VERSION "HIPBNYYYYYYYYYYYYYYYYYYYYYYYYYYYYYYYYYYYYY/4/%%%/4/'%**4YYY///"

NS_ :

BS_:

BU_: DBG VCU BMS MCM DCU DAQ S2C

BO_ 2147483904 VCU_RR_Motor: 4 VCU
 SG_ VCU_RR_Current : 7|32@0- (0.001,0) [-2147.483|2147.483] "A" Vector__XXX

BO_ 2147483905 VCU_RL_Motor: 4 VCU
 SG_ VCU_RL_Current : 7|32@0- (0.001,0) [-2147.483|2147.483] "A" Vector__XXX

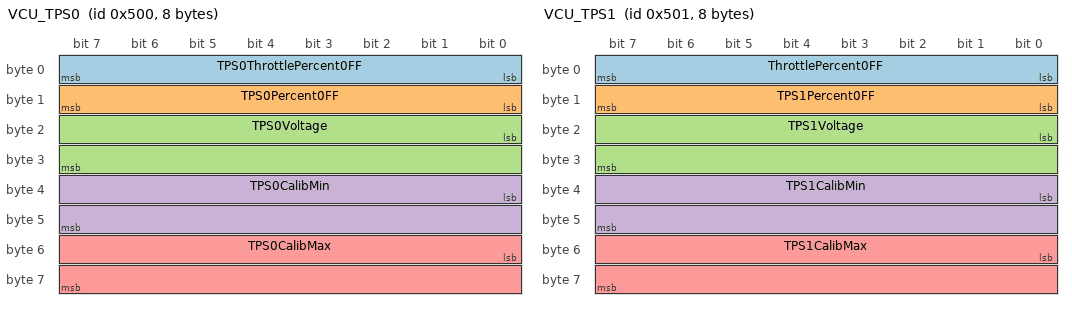
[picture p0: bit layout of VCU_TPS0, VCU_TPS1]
BO_ 1280 VCU_TPS0: 8 VCU
 SG_ TPS0ThrottlePercent0FF : 0|8@1+ (0.392156862746,0) [0|100.00000000023] "%" VCU
 SG_ TPS0Percent0FF : 8|8@1+ (0.392156862746,0) [0|100.00000000023] "%" VCU
 SG_ TPS0Voltage : 16|16@1+ (0.001,0) [0|65.535] "V" VCU
 SG_ TPS0CalibMin : 32|16@1+ (0.001,0) [0|65.535] "V" VCU
 SG_ TPS0CalibMax : 48|16@1+ (0.001,0) [0|65.535] "V" VCU

BO_ 1281 VCU_TPS1: 8 VCU
 SG_ ThrottlePercent0FF : 0|8@1+ (1,0) [0|255] "" VCU
 SG_ TPS1Percent0FF : 8|8@1+ (0.392156862746,0) [0|100.00000000023] "%" VCU
 SG_ TPS1Voltage : 16|16@1+ (0.001,0) [0|65.535] "V" VCU
 SG_ TPS1CalibMin : 32|16@1+ (0.001,0) [0|65.535] "V" VCU
 SG_ TPS1CalibMax : 48|16@1+ (0.001,0) [0|65.535] "V" VCU

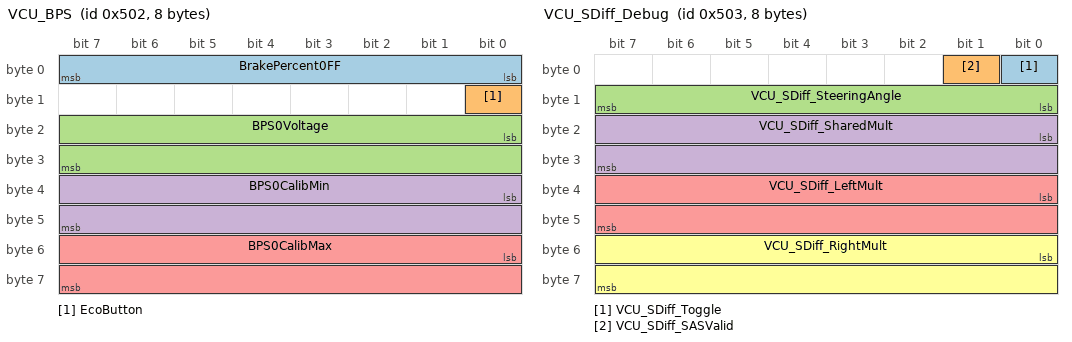
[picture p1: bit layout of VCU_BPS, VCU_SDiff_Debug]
BO_ 1282 VCU_BPS: 8 VCU
SG_ BrakePercent0FF : 0|8@1+ (0.392156862746,0) [0|100.00000000023] "%" VCU
SG_ EcoButton : 8|1@1+ (1,0) [0|1] "" VCU
SG_ BPS0Voltage : 16|16@1+ (0.001,0) [0|65.535] "V" VCU
SG_ BPS0CalibMin : 32|16@1+ (0.001,0) [0|65.535] "V" VCU
SG_ BPS0CalibMax : 48|16@1+ (0.001,0) [0|65.535] "V" VCU

BO_ 1283 VCU_SDiff_Debug: 8 VCU
 SG_ VCU_SDiff_Toggle : 0|1@1+ (1,0) [0|1] "" VCU
 SG_ VCU_SDiff_SASValid : 1|1@1+ (1,0) [0|1] "" VCU
 SG_ VCU_SDiff_SteeringAngle : 8|8@1- (1,0) [-90|90] "deg" VCU
 SG_ VCU_SDiff_SharedMult : 16|16@1+ (0.001,0) [0|1] "" VCU
 SG_ VCU_SDiff_LeftMult : 32|16@1+ (0.001,0) [0|1] "" VCU
 SG_ VCU_SDiff_RightMult : 48|16@1+ (0.001,0) [0|1] "" VCU

BO_ 1284 VCU_SAS: 8 VCU
 SG_ SAS_Voltage : 0|16@1+ (0.001,0) [0|5] "V" VCU

BO_ 1285 VCU_Safety_Checker: 8 VCU
 SG_ VCU_FAULT_TPS_OutOfRange : 0|1@1+ (1,0) [0|1] "" VCU
 SG_ VCU_FAULT_BPS_OutOfRange : 1|1@1+ (1,0) [0|1] "" VCU
 SG_ VCU_FAULT_TPS_PowerFailure : 2|1@1+ (1,0) [0|1] "" VCU
 SG_ VCU_FAULT_BPS_PowerFailure : 3|1@1+ (1,0) [0|1] "" VCU
 SG_ VCU_FAULT_TPS_SignalFailure : 4|1@1+ (1,0) [0|1] "" VCU
 SG_ VCU_FAULT_BPS_SignalFailure : 5|1@1+ (1,0) [0|1] "" VCU
 SG_ VCU_FAULT_TPS_NotCalibrated : 6|1@1+ (1,0) [0|1] "" VCU
 SG_ VCU_FAULT_BPS_NotCalibrated : 7|1@1+ (1,0) [0|1] "" VCU
 SG_ VCU_FAULT_TPS_OutOfSync : 8|1@1+ (1,0) [0|1] "" VCU
 SG_ VCU_FAULT_TPSBPS_Implausible : 10|1@1+ (1,0) [0|1] "" VCU
 SG_ VCU_FAULT_BSPD_SoftFault : 12|1@1+ (1,0) [0|1] "" VCU
 SG_ VCU_FAULT_LVS_BatteryEmpty : 16|1@1+ (1,0) [0|1] "" VCU
 SG_ VCU_FAULT_BMS_OverVoltage : 20|1@1+ (1,0) [0|1] "" VCU
 SG_ VCU_FAULT_BMS_UnderVoltage : 21|1@1+ (1,0) [0|1] "" VCU
 SG_ VCU_FAULT_BMS_OverTemperature : 22|1@1+ (1,0) [0|1] "" VCU
 SG_ VCU_FAULT_BMS_CommunicationLost : 23|1@1+ (1,0) [0|1] "" VCU
 SG_ VCU_FAULT_BMS_CellMismatch : 24|1@1+ (1,0) [0|1] "" VCU
 SG_ VCU_WARNING_LVS_BatteryLow : 32|1@1+ (1,0) [0|1] "" VCU
 SG_ VCU_WARNING_BMS_OverVoltage : 40|1@1+ (1,0) [0|1] "" VCU
 SG_ VCU_WARNING_BMS_UnderVoltage : 41|1@1+ (1,0) [0|1] "" VCU
 SG_ VCU_WARNING_BMS_OverTemperature : 42|1@1+ (1,0) [0|1] "" VCU
 SG_ VCU_WARNING_HVIL_OverrideEn : 38|1@1+ (1,0) [0|1] "" VCU
 SG_ VCU_WARNING_SAFETY_BypassEn : 39|1@1+ (1,0) [0|1] "" VCU
 SG_ VCU_NOTICE_HVIL_TermSenseLost : 48|1@1+ (1,0) [0|1] "" VCU
 SG_ VCU_NOTICE_BMS_Over75kW : 52|1@1+ (1,0) [0|1] "" VCU
 SG_ VCU_NOTICE_MCM_Over75kW : 53|1@1+ (1,0) [0|1] "" VCU

BO_ 1286 Low_Voltage: 8 DAQ
 SG_ Voltage : 0|16@1+ (0.001,0) [0|20] "V" VCU
 SG_ StateOfCharge : 16|8@1+ (1,0) [0|100] "%" VCU

BO_ 1287 MCM_RTD_HVIL: 8 VCU
 SG_ HVIL_Active : 0|1@1+ (1,0) [0|1] "" VCU

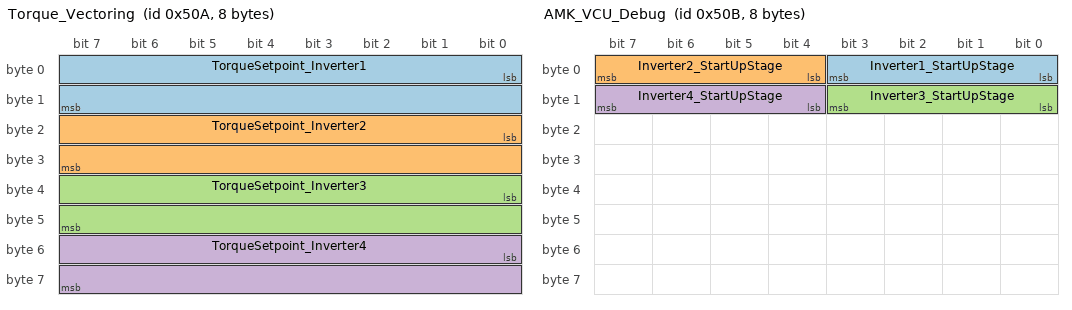
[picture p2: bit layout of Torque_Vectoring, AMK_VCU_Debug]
BO_ 1290 Torque_Vectoring: 8 mcm
 SG_ TorqueSetpoint_Inverter1 : 0|16@1- (0.01,0) [-5|5] "%Nm" Vector__XXX
 SG_ TorqueSetpoint_Inverter2 : 16|16@1- (0.01,0) [-5|5] "%Nm" Vector__XXX
 SG_ TorqueSetpoint_Inverter3 : 32|16@1- (0.01,0) [-5|5] "%Nm" Vector__XXX
 SG_ TorqueSetpoint_Inverter4 : 48|16@1- (0.01,0) [-5|5] "%Nm" Vector__XXX

BO_ 1291 AMK_VCU_Debug: 8 mcm
 SG_ Inverter1_StartUpStage : 0|4@1+ (1,0) [0|10] "" VCU
 SG_ Inverter2_StartUpStage : 4|4@1+ (1,0) [0|10] "" VCU
 SG_ Inverter3_StartUpStage : 8|4@1+ (1,0) [0|10] "" VCU
 SG_ Inverter4_StartUpStage : 12|4@1+ (1,0) [0|10] "" VCU

BO_ 1292 DRS_SAS: 8 DAQ
 SG_ DRS_Enable : 16|8@1+ (1,0) [0|1] "Enable" VCU
 SG_ DRS_Mode : 24|8@1+ (1,0) [0|3] "Selection" VCU

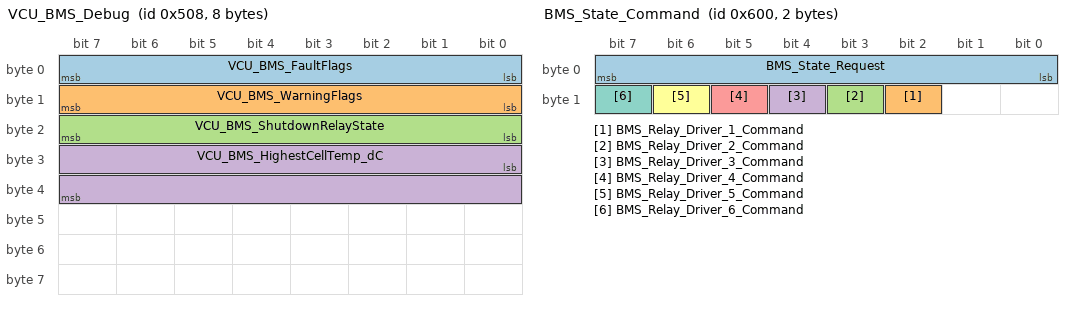
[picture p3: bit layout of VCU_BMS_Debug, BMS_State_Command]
BO_ 1288 VCU_BMS_Debug: 8 VCU
 SG_ VCU_BMS_FaultFlags : 0|8@1+ (1,0) [0|255] "" VCU
 SG_ VCU_BMS_WarningFlags : 8|8@1+ (1,0) [0|255] "" VCU
 SG_ VCU_BMS_ShutdownRelayState : 16|8@1+ (1,0) [0|255] "" VCU
 SG_ VCU_BMS_HighestCellTemp_dC : 24|16@1- (0.1,0) [-3276.8|3276.7] "C" VCU

BO_ 1536 BMS_State_Command: 2 VCU
 SG_ BMS_State_Request : 0|8@1+ (1,0) [0|4] "" Vector__XXX
 SG_ BMS_Relay_Driver_1_Command : 10|1@1+ (1,0) [0|1] "" Vector__XXX
 SG_ BMS_Relay_Driver_2_Command : 11|1@1+ (1,0) [0|1] "" Vector__XXX
 SG_ BMS_Relay_Driver_3_Command : 12|1@1+ (1,0) [0|1] "" Vector__XXX
 SG_ BMS_Relay_Driver_4_Command : 13|1@1+ (1,0) [0|1] "" Vector__XXX
 SG_ BMS_Relay_Driver_5_Command : 14|1@1+ (1,0) [0|1] "" Vector__XXX
 SG_ BMS_Relay_Driver_6_Command : 15|1@1+ (1,0) [0|1] "" Vector__XXX

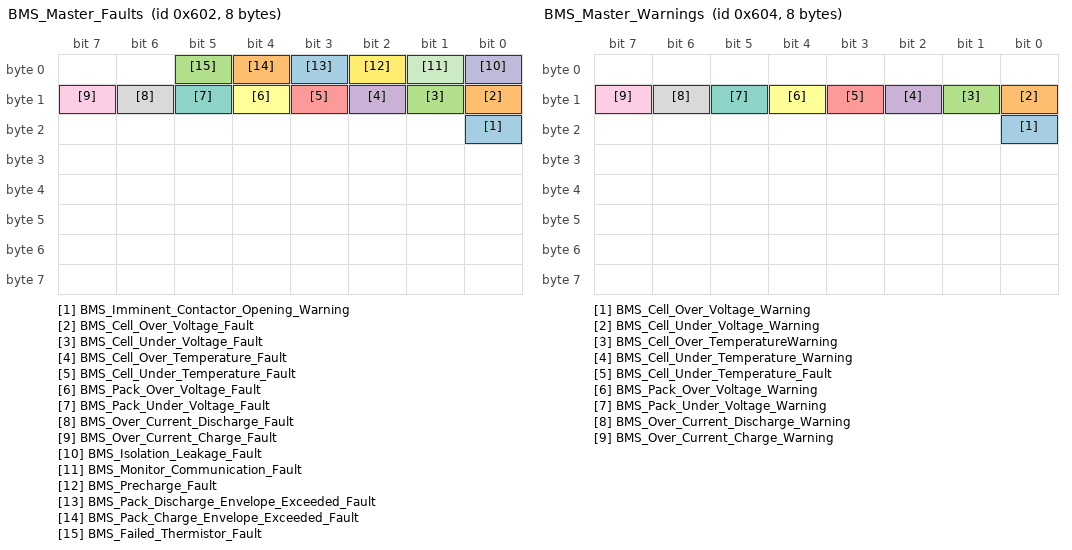
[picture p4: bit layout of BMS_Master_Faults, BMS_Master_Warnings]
BO_ 1538 BMS_Master_Faults: 8 BMS1000M
 SG_ BMS_Imminent_Contactor_Opening_Warning : 16|1@1+ (1,0) [0|1] "" Vector__XXX
 SG_ BMS_Cell_Over_Voltage_Fault : 8|1@1+ (1,0) [0|1] "" Vector__XXX
 SG_ BMS_Cell_Under_Voltage_Fault : 9|1@1+ (1,0) [0|1] "" Vector__XXX
 SG_ BMS_Cell_Over_Temperature_Fault : 10|1@1+ (1,0) [0|1] "" Vector__XXX
 SG_ BMS_Cell_Under_Temperature_Fault : 11|1@1+ (1,0) [0|1] "" Vector__XXX
 SG_ BMS_Pack_Over_Voltage_Fault : 12|1@1+ (1,0) [0|1] "" Vector__XXX
 SG_ BMS_Pack_Under_Voltage_Fault : 13|1@1+ (1,0) [0|1] "" Vector__XXX
 SG_ BMS_Over_Current_Discharge_Fault : 14|1@1+ (1,0) [0|1] "" Vector__XXX
 SG_ BMS_Over_Current_Charge_Fault : 15|1@1+ (1,0) [0|1] "" Vector__XXX
 SG_ BMS_Isolation_Leakage_Fault : 0|1@1+ (1,0) [0|1] "" Vector__XXX
 SG_ BMS_Monitor_Communication_Fault : 1|1@1+ (1,0) [0|1] "" Vector__XXX
 SG_ BMS_Precharge_Fault : 2|1@1+ (1,0) [0|1] "" Vector__XXX
 SG_ BMS_Pack_Discharge_Envelope_Exceeded_Fault : 3|1@1+ (1,0) [0|1] "" Vector__XXX
 SG_ BMS_Pack_Charge_Envelope_Exceeded_Fault : 4|1@1+ (1,0) [0|1] "" Vector__XXX
 SG_ BMS_Failed_Thermistor_Fault : 5|1@1+ (1,0) [0|1] "" Vector__XXX

BO_ 1540 BMS_Master_Warnings: 8 BMS1000M
 SG_ BMS_Cell_Over_Voltage_Warning : 16|1@1+ (1,0) [0|1] "" Vector__XXX
 SG_ BMS_Cell_Under_Voltage_Warning : 8|1@1+ (1,0) [0|1] "" Vector__XXX
 SG_ BMS_Cell_Over_TemperatureWarning : 9|1@1+ (1,0) [0|1] "" Vector__XXX
 SG_ BMS_Cell_Under_Temperature_Warning : 10|1@1+ (1,0) [0|1] "" Vector__XXX
 SG_ BMS_Cell_Under_Temperature_Fault : 11|1@1+ (1,0) [0|1] "" Vector__XXX
 SG_ BMS_Pack_Over_Voltage_Warning : 12|1@1+ (1,0) [0|1] "" Vector__XXX
 SG_ BMS_Pack_Under_Voltage_Warning : 13|1@1+ (1,0) [0|1] "" Vector__XXX
 SG_ BMS_Over_Current_Discharge_Warning : 14|1@1+ (1,0) [0|1] "" Vector__XXX
 SG_ BMS_Over_Current_Charge_Warning : 15|1@1+ (1,0) [0|1] "" Vector__XXX

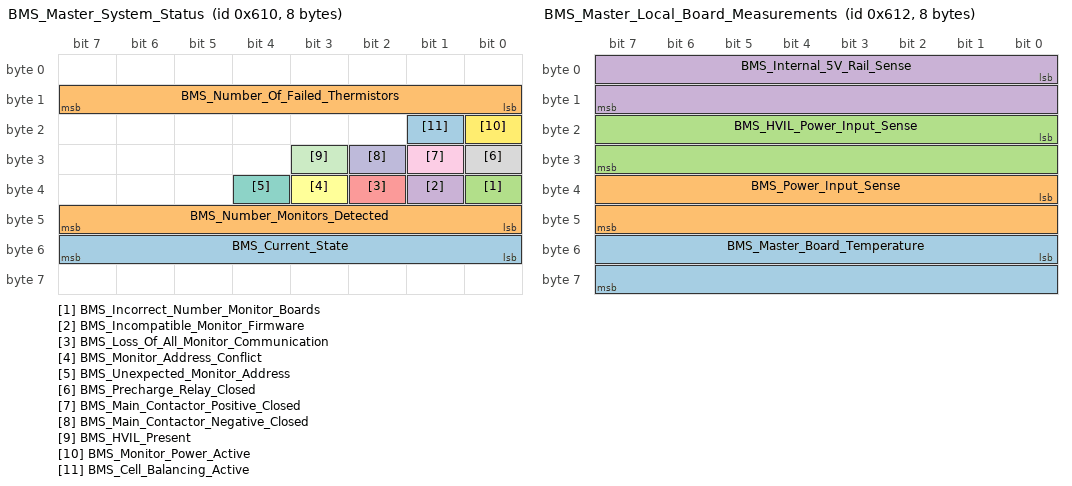
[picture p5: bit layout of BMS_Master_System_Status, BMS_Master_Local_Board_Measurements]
BO_ 1552 BMS_Master_System_Status: 8 BMS1000M
 SG_ BMS_Current_State : 48|8@1+ (1,0) [0|6] "" Vector__XXX
 SG_ BMS_Number_Monitors_Detected : 40|8@1+ (1,0) [0|255] "" Vector__XXX
 SG_ BMS_Incorrect_Number_Monitor_Boards : 32|1@1+ (1,0) [0|1] "" Vector__XXX
 SG_ BMS_Incompatible_Monitor_Firmware : 33|1@1+ (1,0) [0|1] "" Vector__XXX
 SG_ BMS_Loss_Of_All_Monitor_Communication : 34|1@1+ (1,0) [0|1] "" Vector__XXX
 SG_ BMS_Monitor_Address_Conflict : 35|1@1+ (1,0) [0|1] "" Vector__XXX
 SG_ BMS_Unexpected_Monitor_Address : 36|1@1+ (1,0) [0|1] "" Vector__XXX
 SG_ BMS_Precharge_Relay_Closed : 24|1@1+ (1,0) [0|1] "" Vector__XXX
 SG_ BMS_Main_Contactor_Positive_Closed : 25|1@1+ (1,0) [0|1] "" Vector__XXX
 SG_ BMS_Main_Contactor_Negative_Closed : 26|1@1+ (1,0) [0|1] "" Vector__XXX
 SG_ BMS_HVIL_Present : 27|1@1+ (1,0) [0|1] "" Vector__XXX
 SG_ BMS_Monitor_Power_Active : 16|1@1+ (1,0) [0|1] "" Vector__XXX
 SG_ BMS_Cell_Balancing_Active : 17|1@1+ (1,0) [0|1] "" Vector__XXX
 SG_ BMS_Number_Of_Failed_Thermistors : 8|8@1+ (1,0) [0|255] "" Vector__XXX

BO_ 1553 BMS_Pack_Safe_OE: 8 BMS1000M
 SG_ BMS_Charger_Constant_Voltage_Setpoint : 32|16@1+ (0.1,0) [0|1000] "V" Vector__XXX
 SG_ BMS_Maximum_Discharge_Current_Allowed : 16|16@1+ (0.1,0) [0|2500] "A" Vector__XXX
 SG_ BMS_Maximum_Charge_Current_Allowed : 0|16@1+ (0.1,0) [0|2500] "A" Vector__XXX

BO_ 1554 BMS_Master_Local_Board_Measurements: 8 BMS1000M
 SG_ BMS_Master_Board_Temperature : 48|16@1- (0.1,0) [-50|150] "DegC" Vector__XXX
 SG_ BMS_Power_Input_Sense : 32|16@1+ (0.001,0) [0|36] "V" Vector__XXX
 SG_ BMS_HVIL_Power_Input_Sense : 16|16@1+ (0.001,0) [0|36] "V" Vector__XXX
 SG_ BMS_Internal_5V_Rail_Sense : 0|16@1+ (0.001,0) [0|7.5] "V" Vector__XXX

BO_ 1568 BMS_Pack_Level_Measurements_1: 8 BMS1000M
 SG_ BMS_Pack_Voltage : 32|32@1+ (0.001,0) [0|1500] "V" Vector__XXX
 SG_ BMS_Pack_Current : 0|32@1- (0.001,0) [-2500|2500] "A" Vector__XXX

BO_ 1569 BMS_Pack_Level_Measurements_2: 8 BMS1000M
 SG_ BMS_State_Of_Charge : 48|16@1+ (0.1,0) [0|100] "%" Vector__XXX
 SG_ BMS_State_Of_Health : 32|16@1+ (0.1,0) [0|100] "%" Vector__XXX
 SG_ BMS_Amp_Hours_Remaining : 16|16@1+ (0.1,0) [0|6000] "Ah" Vector__XXX

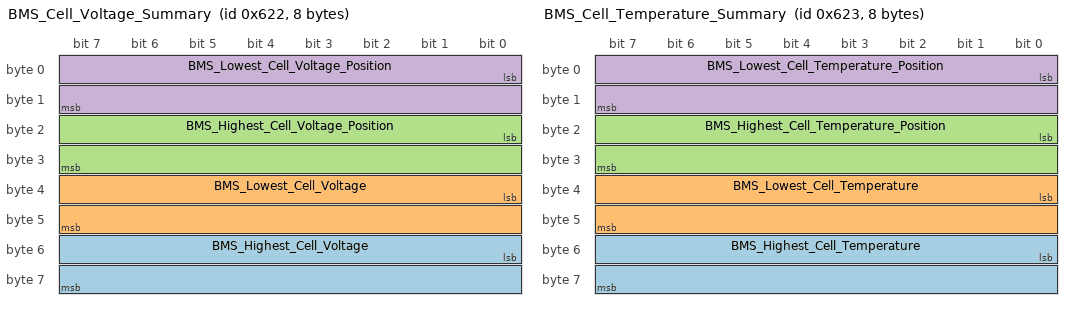
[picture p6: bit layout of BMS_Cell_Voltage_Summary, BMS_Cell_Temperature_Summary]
BO_ 1570 BMS_Cell_Voltage_Summary: 8 BMS1000M
 SG_ BMS_Highest_Cell_Voltage : 48|16@1+ (0.001,0) [0|5] "V" Vector__XXX
 SG_ BMS_Lowest_Cell_Voltage : 32|16@1+ (0.001,0) [0|5] "V" Vector__XXX
 SG_ BMS_Highest_Cell_Voltage_Position : 16|16@1+ (1,0) [0|500] "" Vector__XXX
 SG_ BMS_Lowest_Cell_Voltage_Position : 0|16@1+ (1,0) [0|500] "" Vector__XXX

BO_ 1571 BMS_Cell_Temperature_Summary: 8 BMS1000M
 SG_ BMS_Highest_Cell_Temperature : 48|16@1- (0.1,0) [-50|150] "DegC" Vector__XXX
 SG_ BMS_Lowest_Cell_Temperature : 32|16@1- (0.1,0) [-50|150] "DegC" Vector__XXX
 SG_ BMS_Highest_Cell_Temperature_Position : 16|16@1+ (1,0) [0|500] "" Vector__XXX
 SG_ BMS_Lowest_Cell_Temperature_Position : 0|16@1+ (1,0) [0|500] "" Vector__XXX

BO_ 1788 BMS_Configuration_Information: 8 BMS1000M
 SG_ BMS_Number_Of_Cells_Configured : 16|16@1+ (1,0) [0|500] "" Vector__XXX
 SG_ BMS_Number_Of_Thermistors_Configured : 0|16@1+ (1,0) [0|500] "" Vector__XXX

BO_ 1790 BMS_Firmware_Version_Information: 8 BMS1000M
 SG_ BMS_Major_Version_Number : 16|8@1+ (1,0) [0|100] "" Vector__XXX
 SG_ BMS_Minor_Version_Number : 8|8@1+ (1,0) [0|100] "" Vector__XXX
 SG_ BMS_Revision_Number : 0|8@1+ (1,0) [0|200] "" Vector__XXX

BO_ 1794 MCM_RegenModeICSent: 8 MCM
   SG_ RegenMode : 0|3@1+ (1,0) [0|3] "Regen mode" MCM

BO_ 1572 BMS_Pack_Level_Measurements_3: 8 BMS1000M
 SG_ BMS_Sum_Of_Cells_Voltage : 32|32@1+ (0.001,0) [0|1500] "V" Vector__XXX
 SG_ BMS_Precharge_Voltage : 0|32@1+ (0.001,0) [0|1500] "V" Vector__XXX

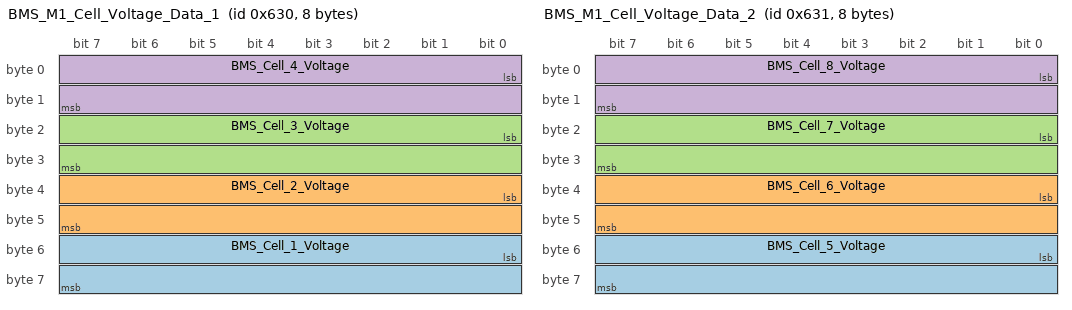
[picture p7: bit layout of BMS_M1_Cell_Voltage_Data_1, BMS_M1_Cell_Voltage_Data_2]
BO_ 1584 BMS_M1_Cell_Voltage_Data_1: 8 BMS1000M
 SG_ BMS_Cell_1_Voltage : 48|16@1+ (0.001,0) [0|6] "V" Vector__XXX
 SG_ BMS_Cell_2_Voltage : 32|16@1+ (0.001,0) [0|6] "V" Vector__XXX
 SG_ BMS_Cell_3_Voltage : 16|16@1+ (0.001,0) [0|6] "V" Vector__XXX
 SG_ BMS_Cell_4_Voltage : 0|16@1+ (0.001,0) [0|6] "V" Vector__XXX

BO_ 1585 BMS_M1_Cell_Voltage_Data_2: 8 BMS1000M
 SG_ BMS_Cell_5_Voltage : 48|16@1+ (0.001,0) [0|6] "V" Vector__XXX
 SG_ BMS_Cell_6_Voltage : 32|16@1+ (0.001,0) [0|6] "V" Vector__XXX
 SG_ BMS_Cell_7_Voltage : 16|16@1+ (0.001,0) [0|6] "V" Vector__XXX
 SG_ BMS_Cell_8_Voltage : 0|16@1+ (0.001,0) [0|6] "V" Vector__XXX

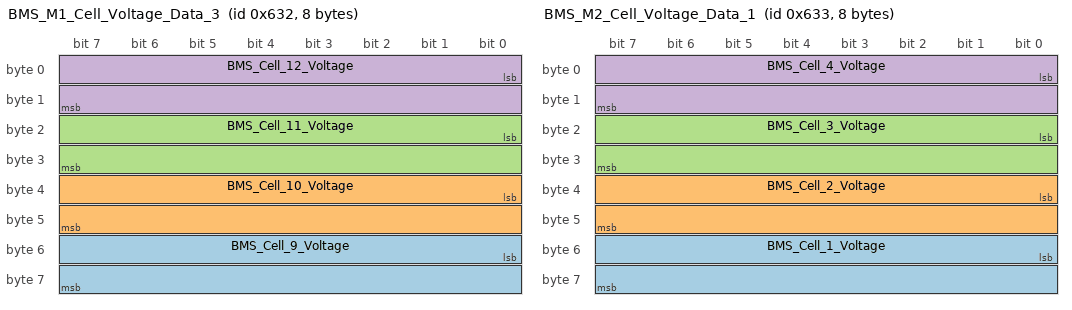
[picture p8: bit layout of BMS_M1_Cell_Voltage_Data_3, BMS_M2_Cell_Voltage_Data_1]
BO_ 1586 BMS_M1_Cell_Voltage_Data_3: 8 BMS1000M
 SG_ BMS_Cell_9_Voltage : 48|16@1+ (0.001,0) [0|6] "V" Vector__XXX
 SG_ BMS_Cell_10_Voltage : 32|16@1+ (0.001,0) [0|6] "V" Vector__XXX
 SG_ BMS_Cell_11_Voltage : 16|16@1+ (0.001,0) [0|6] "V" Vector__XXX
 SG_ BMS_Cell_12_Voltage : 0|16@1+ (0.001,0) [0|6] "V" Vector__XXX

BO_ 1587 BMS_M2_Cell_Voltage_Data_1: 8 BMS1000M
 SG_ BMS_Cell_1_Voltage : 48|16@1+ (0.001,0) [0|6] "C" Vector__XXX
 SG_ BMS_Cell_2_Voltage : 32|16@1+ (0.001,0) [0|6] "C" Vector__XXX
 SG_ BMS_Cell_3_Voltage : 16|16@1+ (0.001,0) [0|6] "C" Vector__XXX
 SG_ BMS_Cell_4_Voltage : 0|16@1+ (0.001,0) [0|6] "C" Vector__XXX

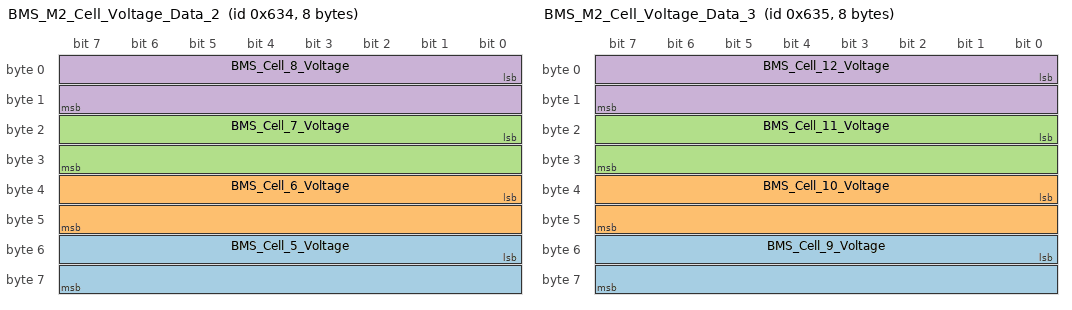
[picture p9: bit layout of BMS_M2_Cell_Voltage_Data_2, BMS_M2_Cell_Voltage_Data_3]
BO_ 1588 BMS_M2_Cell_Voltage_Data_2: 8 BMS1000M
 SG_ BMS_Cell_5_Voltage : 48|16@1+ (0.001,0) [0|6] "V" Vector__XXX
 SG_ BMS_Cell_6_Voltage : 32|16@1+ (0.001,0) [0|6] "V" Vector__XXX
 SG_ BMS_Cell_7_Voltage : 16|16@1+ (0.001,0) [0|6] "V" Vector__XXX
 SG_ BMS_Cell_8_Voltage : 0|16@1+ (0.001,0) [0|6] "V" Vector__XXX

BO_ 1589 BMS_M2_Cell_Voltage_Data_3: 8 BMS1000M
 SG_ BMS_Cell_9_Voltage : 48|16@1+ (0.001,0) [0|6] "V" Vector__XXX
 SG_ BMS_Cell_10_Voltage : 32|16@1+ (0.001,0) [0|6] "V" Vector__XXX
 SG_ BMS_Cell_11_Voltage : 16|16@1+ (0.001,0) [0|6] "V" Vector__XXX
 SG_ BMS_Cell_12_Voltage : 0|16@1+ (0.001,0) [0|6] "V" Vector__XXX

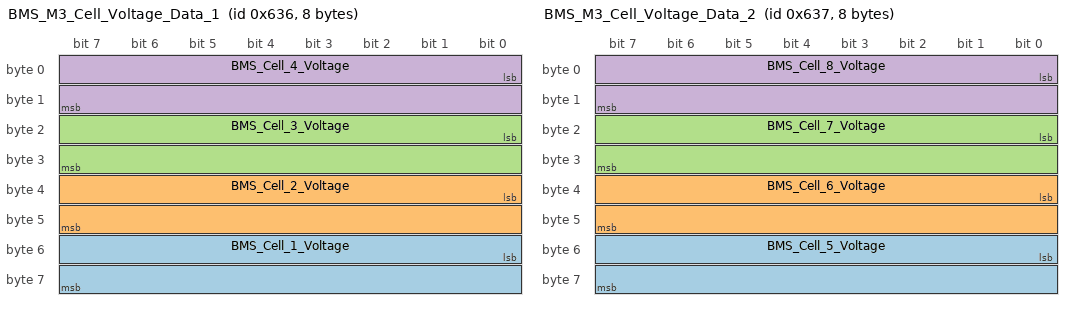
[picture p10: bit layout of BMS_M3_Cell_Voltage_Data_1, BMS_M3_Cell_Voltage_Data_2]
BO_ 1590 BMS_M3_Cell_Voltage_Data_1: 8 BMS1000M
 SG_ BMS_Cell_1_Voltage : 48|16@1+ (0.001,0) [0|6] "V" Vector__XXX
 SG_ BMS_Cell_2_Voltage : 32|16@1+ (0.001,0) [0|6] "V" Vector__XXX
 SG_ BMS_Cell_3_Voltage : 16|16@1+ (0.001,0) [0|6] "V" Vector__XXX
 SG_ BMS_Cell_4_Voltage : 0|16@1+ (0.001,0) [0|6] "V" Vector__XXX

BO_ 1591 BMS_M3_Cell_Voltage_Data_2: 8 BMS1000M
 SG_ BMS_Cell_5_Voltage : 48|16@1+ (0.001,0) [0|6] "V" Vector__XXX
 SG_ BMS_Cell_6_Voltage : 32|16@1+ (0.001,0) [0|6] "V" Vector__XXX
 SG_ BMS_Cell_7_Voltage : 16|16@1+ (0.001,0) [0|6] "V" Vector__XXX
 SG_ BMS_Cell_8_Voltage : 0|16@1+ (0.001,0) [0|6] "V" Vector__XXX

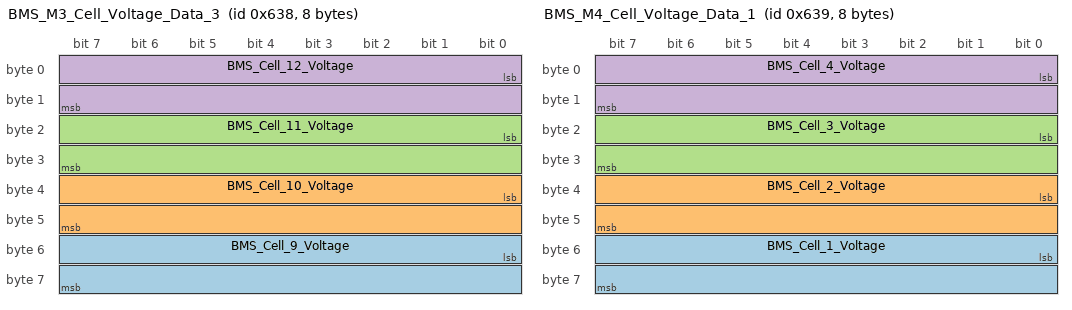
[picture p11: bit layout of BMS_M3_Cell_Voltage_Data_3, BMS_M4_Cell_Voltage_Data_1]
BO_ 1592 BMS_M3_Cell_Voltage_Data_3: 8 BMS1000M
 SG_ BMS_Cell_9_Voltage : 48|16@1+ (0.001,0) [0|6] "V" Vector__XXX
 SG_ BMS_Cell_10_Voltage : 32|16@1+ (0.001,0) [0|6] "V" Vector__XXX
 SG_ BMS_Cell_11_Voltage : 16|16@1+ (0.001,0) [0|6] "V" Vector__XXX
 SG_ BMS_Cell_12_Voltage : 0|16@1+ (0.001,0) [0|6] "V" Vector__XXX

BO_ 1593 BMS_M4_Cell_Voltage_Data_1: 8 BMS1000M
 SG_ BMS_Cell_1_Voltage : 48|16@1+ (0.001,0) [0|6] "V" Vector__XXX
 SG_ BMS_Cell_2_Voltage : 32|16@1+ (0.001,0) [0|6] "V" Vector__XXX
 SG_ BMS_Cell_3_Voltage : 16|16@1+ (0.001,0) [0|6] "V" Vector__XXX
 SG_ BMS_Cell_4_Voltage : 0|16@1+ (0.001,0) [0|6] "V" Vector__XXX

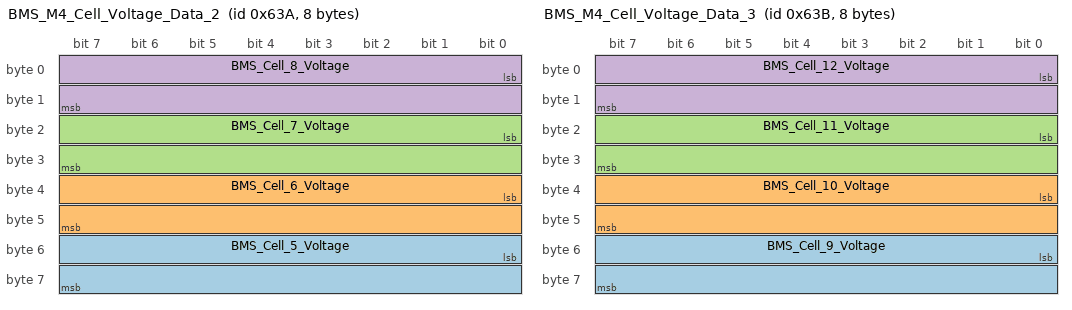
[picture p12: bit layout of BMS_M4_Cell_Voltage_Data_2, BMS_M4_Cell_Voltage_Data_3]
BO_ 1594 BMS_M4_Cell_Voltage_Data_2: 8 BMS1000M
 SG_ BMS_Cell_5_Voltage : 48|16@1+ (0.001,0) [0|6] "V" Vector__XXX
 SG_ BMS_Cell_6_Voltage : 32|16@1+ (0.001,0) [0|6] "V" Vector__XXX
 SG_ BMS_Cell_7_Voltage : 16|16@1+ (0.001,0) [0|6] "V" Vector__XXX
 SG_ BMS_Cell_8_Voltage : 0|16@1+ (0.001,0) [0|6] "V" Vector__XXX

BO_ 1595 BMS_M4_Cell_Voltage_Data_3: 8 BMS1000M
 SG_ BMS_Cell_9_Voltage : 48|16@1+ (0.001,0) [0|6] "V" Vector__XXX
 SG_ BMS_Cell_10_Voltage : 32|16@1+ (0.001,0) [0|6] "V" Vector__XXX
 SG_ BMS_Cell_11_Voltage : 16|16@1+ (0.001,0) [0|6] "V" Vector__XXX
 SG_ BMS_Cell_12_Voltage : 0|16@1+ (0.001,0) [0|6] "V" Vector__XXX

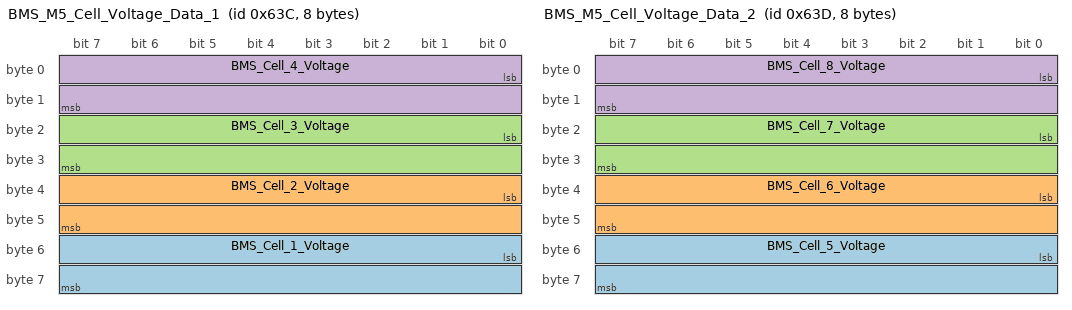
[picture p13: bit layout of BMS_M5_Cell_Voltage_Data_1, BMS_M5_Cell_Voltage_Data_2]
BO_ 1596 BMS_M5_Cell_Voltage_Data_1: 8 BMS1000M
 SG_ BMS_Cell_1_Voltage : 48|16@1+ (0.001,0) [0|6] "V" Vector__XXX
 SG_ BMS_Cell_2_Voltage : 32|16@1+ (0.001,0) [0|6] "V" Vector__XXX
 SG_ BMS_Cell_3_Voltage : 16|16@1+ (0.001,0) [0|6] "V" Vector__XXX
 SG_ BMS_Cell_4_Voltage : 0|16@1+ (0.001,0) [0|6] "V" Vector__XXX

BO_ 1597 BMS_M5_Cell_Voltage_Data_2: 8 BMS1000M
 SG_ BMS_Cell_5_Voltage : 48|16@1+ (0.001,0) [0|6] "V" Vector__XXX
 SG_ BMS_Cell_6_Voltage : 32|16@1+ (0.001,0) [0|6] "V" Vector__XXX
 SG_ BMS_Cell_7_Voltage : 16|16@1+ (0.001,0) [0|6] "V" Vector__XXX
 SG_ BMS_Cell_8_Voltage : 0|16@1+ (0.001,0) [0|6] "V" Vector__XXX

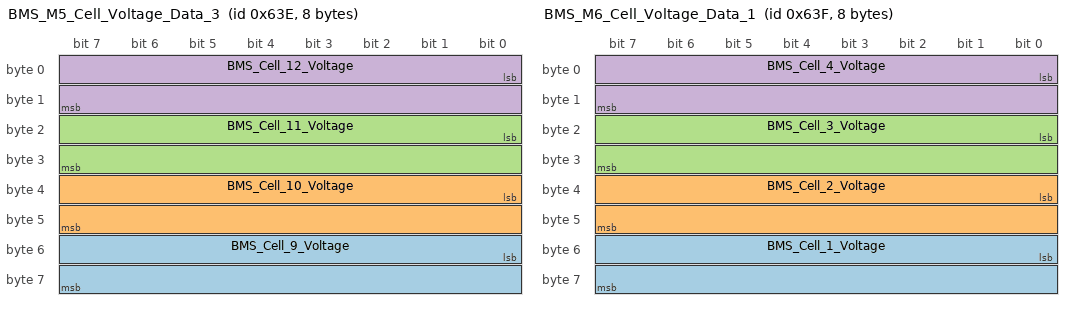
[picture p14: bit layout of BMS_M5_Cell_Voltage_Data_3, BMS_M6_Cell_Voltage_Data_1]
BO_ 1598 BMS_M5_Cell_Voltage_Data_3: 8 BMS1000M
 SG_ BMS_Cell_9_Voltage : 48|16@1+ (0.001,0) [0|6] "V" Vector__XXX
 SG_ BMS_Cell_10_Voltage : 32|16@1+ (0.001,0) [0|6] "V" Vector__XXX
 SG_ BMS_Cell_11_Voltage : 16|16@1+ (0.001,0) [0|6] "V" Vector__XXX
 SG_ BMS_Cell_12_Voltage : 0|16@1+ (0.001,0) [0|6] "V" Vector__XXX

BO_ 1599 BMS_M6_Cell_Voltage_Data_1: 8 BMS1000M
 SG_ BMS_Cell_1_Voltage : 48|16@1+ (0.001,0) [0|6] "V" Vector__XXX
 SG_ BMS_Cell_2_Voltage : 32|16@1+ (0.001,0) [0|6] "V" Vector__XXX
 SG_ BMS_Cell_3_Voltage : 16|16@1+ (0.001,0) [0|6] "V" Vector__XXX
 SG_ BMS_Cell_4_Voltage : 0|16@1+ (0.001,0) [0|6] "V" Vector__XXX

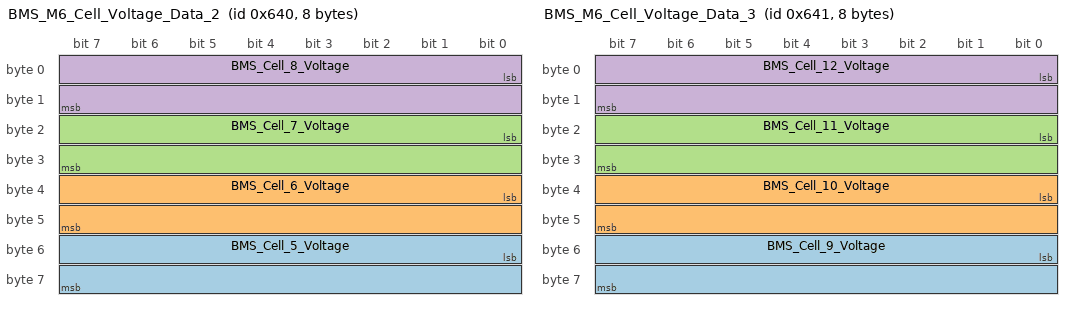
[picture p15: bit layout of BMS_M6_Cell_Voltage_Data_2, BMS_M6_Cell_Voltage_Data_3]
BO_ 1600 BMS_M6_Cell_Voltage_Data_2: 8 BMS1000M
 SG_ BMS_Cell_5_Voltage : 48|16@1+ (0.001,0) [0|6] "V" Vector__XXX
 SG_ BMS_Cell_6_Voltage : 32|16@1+ (0.001,0) [0|6] "V" Vector__XXX
 SG_ BMS_Cell_7_Voltage : 16|16@1+ (0.001,0) [0|6] "V" Vector__XXX
 SG_ BMS_Cell_8_Voltage : 0|16@1+ (0.001,0) [0|6] "V" Vector__XXX

BO_ 1601 BMS_M6_Cell_Voltage_Data_3: 8 BMS1000M
 SG_ BMS_Cell_9_Voltage : 48|16@1+ (0.001,0) [0|6] "V" Vector__XXX
 SG_ BMS_Cell_10_Voltage : 32|16@1+ (0.001,0) [0|6] "V" Vector__XXX
 SG_ BMS_Cell_11_Voltage : 16|16@1+ (0.001,0) [0|6] "V" Vector__XXX
 SG_ BMS_Cell_12_Voltage : 0|16@1+ (0.001,0) [0|6] "V" Vector__XXX

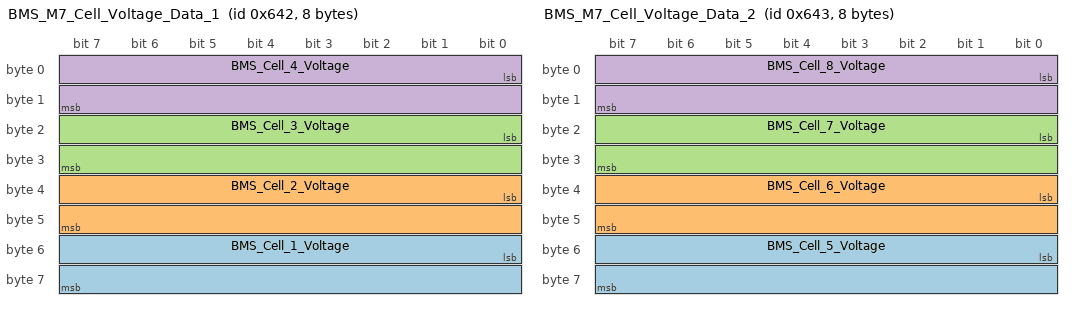
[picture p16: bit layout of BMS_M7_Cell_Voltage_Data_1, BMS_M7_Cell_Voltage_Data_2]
BO_ 1602 BMS_M7_Cell_Voltage_Data_1: 8 BMS1000M
 SG_ BMS_Cell_1_Voltage : 48|16@1+ (0.001,0) [0|6] "V" Vector__XXX
 SG_ BMS_Cell_2_Voltage : 32|16@1+ (0.001,0) [0|6] "V" Vector__XXX
 SG_ BMS_Cell_3_Voltage : 16|16@1+ (0.001,0) [0|6] "V" Vector__XXX
 SG_ BMS_Cell_4_Voltage : 0|16@1+ (0.001,0) [0|6] "V" Vector__XXX

BO_ 1603 BMS_M7_Cell_Voltage_Data_2: 8 BMS1000M
 SG_ BMS_Cell_5_Voltage : 48|16@1+ (0.001,0) [0|6] "V" Vector__XXX
 SG_ BMS_Cell_6_Voltage : 32|16@1+ (0.001,0) [0|6] "V" Vector__XXX
 SG_ BMS_Cell_7_Voltage : 16|16@1+ (0.001,0) [0|6] "V" Vector__XXX
 SG_ BMS_Cell_8_Voltage : 0|16@1+ (0.001,0) [0|6] "V" Vector__XXX

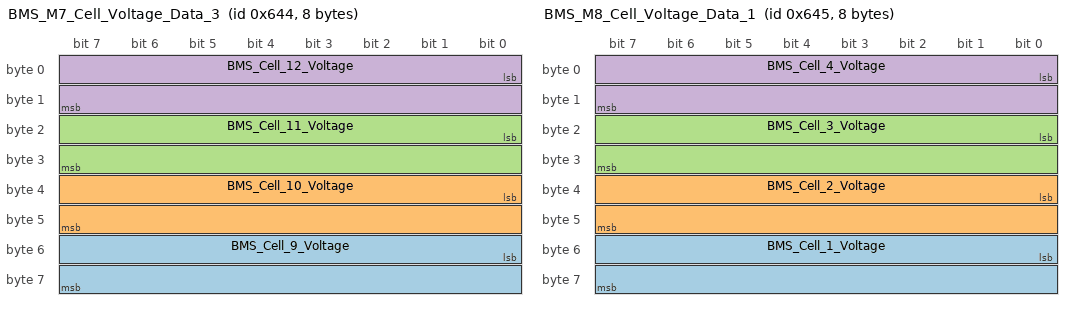
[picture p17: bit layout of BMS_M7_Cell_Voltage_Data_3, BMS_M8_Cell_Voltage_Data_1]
BO_ 1604 BMS_M7_Cell_Voltage_Data_3: 8 BMS1000M
 SG_ BMS_Cell_9_Voltage : 48|16@1+ (0.001,0) [0|6] "V" Vector__XXX
 SG_ BMS_Cell_10_Voltage : 32|16@1+ (0.001,0) [0|6] "V" Vector__XXX
 SG_ BMS_Cell_11_Voltage : 16|16@1+ (0.001,0) [0|6] "V" Vector__XXX
 SG_ BMS_Cell_12_Voltage : 0|16@1+ (0.001,0) [0|6] "V" Vector__XXX

BO_ 1605 BMS_M8_Cell_Voltage_Data_1: 8 BMS1000M
 SG_ BMS_Cell_1_Voltage : 48|16@1+ (0.001,0) [0|6] "V" Vector__XXX
 SG_ BMS_Cell_2_Voltage : 32|16@1+ (0.001,0) [0|6] "V" Vector__XXX
 SG_ BMS_Cell_3_Voltage : 16|16@1+ (0.001,0) [0|6] "V" Vector__XXX
 SG_ BMS_Cell_4_Voltage : 0|16@1+ (0.001,0) [0|6] "V" Vector__XXX

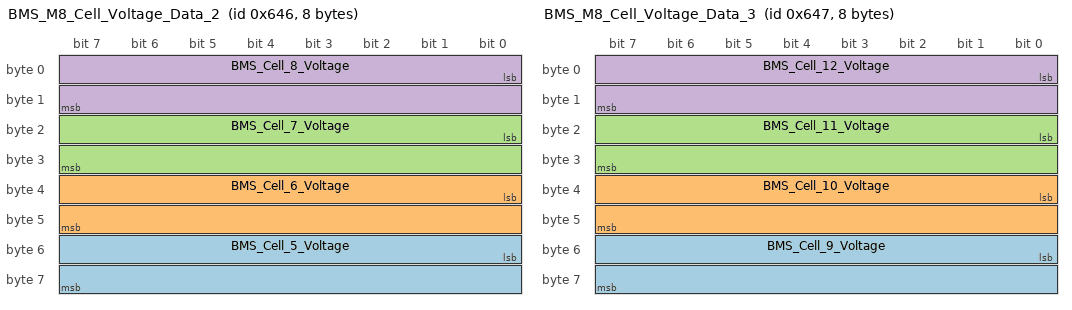
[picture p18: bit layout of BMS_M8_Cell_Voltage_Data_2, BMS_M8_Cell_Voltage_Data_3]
BO_ 1606 BMS_M8_Cell_Voltage_Data_2: 8 BMS1000M
 SG_ BMS_Cell_5_Voltage : 48|16@1+ (0.001,0) [0|6] "V" Vector__XXX
 SG_ BMS_Cell_6_Voltage : 32|16@1+ (0.001,0) [0|6] "V" Vector__XXX
 SG_ BMS_Cell_7_Voltage : 16|16@1+ (0.001,0) [0|6] "V" Vector__XXX
 SG_ BMS_Cell_8_Voltage : 0|16@1+ (0.001,0) [0|6] "V" Vector__XXX

BO_ 1607 BMS_M8_Cell_Voltage_Data_3: 8 BMS1000M
 SG_ BMS_Cell_9_Voltage : 48|16@1+ (0.001,0) [0|6] "V" Vector__XXX
 SG_ BMS_Cell_10_Voltage : 32|16@1+ (0.001,0) [0|6] "V" Vector__XXX
 SG_ BMS_Cell_11_Voltage : 16|16@1+ (0.001,0) [0|6] "V" Vector__XXX
 SG_ BMS_Cell_12_Voltage : 0|16@1+ (0.001,0) [0|6] "V" Vector__XXX

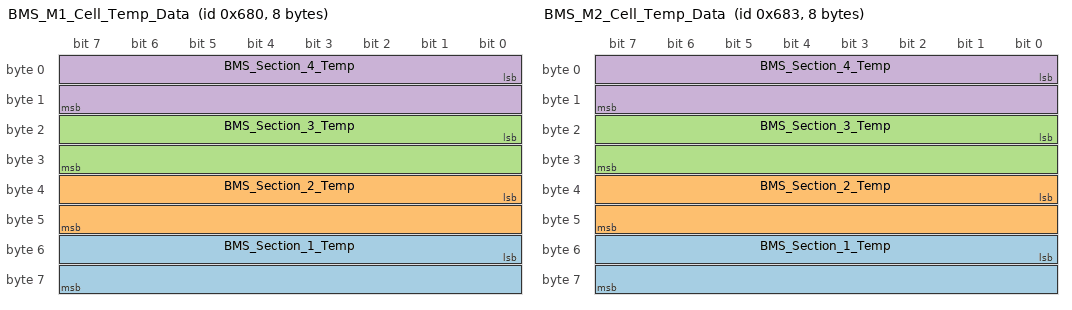
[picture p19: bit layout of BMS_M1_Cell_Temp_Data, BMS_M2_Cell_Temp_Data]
BO_ 1664 BMS_M1_Cell_Temp_Data: 8 BMS1000M
 SG_ BMS_Section_1_Temp : 48|16@1+ (0.1,0) [0|6] "C" Vector__XXX
 SG_ BMS_Section_2_Temp : 32|16@1+ (0.1,0) [0|6] "C" Vector__XXX
 SG_ BMS_Section_3_Temp : 16|16@1+ (0.1,0) [0|6] "C" Vector__XXX
 SG_ BMS_Section_4_Temp : 0|16@1+ (0.1,0) [0|6] "C" Vector__XXX

BO_ 1667 BMS_M2_Cell_Temp_Data: 8 BMS1000M
 SG_ BMS_Section_1_Temp : 48|16@1+ (0.1,0) [0|6] "C" Vector__XXX
 SG_ BMS_Section_2_Temp : 32|16@1+ (0.1,0) [0|6] "C" Vector__XXX
 SG_ BMS_Section_3_Temp : 16|16@1+ (0.1,0) [0|6] "C" Vector__XXX
 SG_ BMS_Section_4_Temp : 0|16@1+ (0.1,0) [0|6] "C" Vector__XXX

BO_ 1670 BMS_M3_Cell_Temp_Data: 8 BMS1000M
 SG_ BMS_Section_1_Temp : 48|16@1+ (0.1,0) [0|6] "C" Vector__XXX
 SG_ BMS_Section_2_Temp : 32|16@1+ (0.1,0) [0|6] "C" Vector__XXX
 SG_ BMS_Section_3_Temp : 16|16@1+ (0.1,0) [0|6] "C" Vector__XXX
 SG_ BMS_Section_4_Temp : 0|16@1+ (0.1,0) [0|6] "C" Vector__XXX

BO_ 1673 BMS_M4_Cell_Temp_Data: 8 BMS1000M
 SG_ BMS_Section_1_Temp : 48|16@1+ (0.1,0) [0|6] "C" Vector__XXX
 SG_ BMS_Section_2_Temp : 32|16@1+ (0.1,0) [0|6] "C" Vector__XXX
 SG_ BMS_Section_3_Temp : 16|16@1+ (0.1,0) [0|6] "C" Vector__XXX
 SG_ BMS_Section_4_Temp : 0|16@1+ (0.1,0) [0|6] "C" Vector__XXX

BO_ 1676 BMS_M5_Cell_Temp_Data: 8 BMS1000M
 SG_ BMS_Section_1_Temp : 48|16@1+ (0.1,0) [0|6] "C" Vector__XXX
 SG_ BMS_Section_2_Temp : 32|16@1+ (0.1,0) [0|6] "C" Vector__XXX
 SG_ BMS_Section_3_Temp : 16|16@1+ (0.1,0) [0|6] "C" Vector__XXX
 SG_ BMS_Section_4_Temp : 0|16@1+ (0.1,0) [0|6] "C" Vector__XXX

BO_ 1679 BMS_M6_Cell_Temp_Data: 8 BMS1000M
 SG_ BMS_Section_1_Temp : 48|16@1+ (0.1,0) [0|6] "C" Vector__XXX
 SG_ BMS_Section_2_Temp : 32|16@1+ (0.1,0) [0|6] "C" Vector__XXX
 SG_ BMS_Section_3_Temp : 16|16@1+ (0.1,0) [0|6] "C" Vector__XXX
 SG_ BMS_Section_4_Temp : 0|16@1+ (0.1,0) [0|6] "C" Vector__XXX

BO_ 1682 BMS_M7_Cell_Temp_Data: 8 BMS1000M
 SG_ BMS_Section_1_Temp : 48|16@1+ (0.1,0) [0|6] "C" Vector__XXX
 SG_ BMS_Section_2_Temp : 32|16@1+ (0.1,0) [0|6] "C" Vector__XXX
 SG_ BMS_Section_3_Temp : 16|16@1+ (0.1,0) [0|6] "C" Vector__XXX
 SG_ BMS_Section_4_Temp : 0|16@1+ (0.1,0) [0|6] "C" Vector__XXX

BO_ 1685 BMS_M8_Cell_Temp_Data: 8 BMS1000M
 SG_ BMS_Section_1_Temp : 48|16@1+ (0.1,0) [0|6] "C" Vector__XXX
 SG_ BMS_Section_2_Temp : 32|16@1+ (0.1,0) [0|6] "C" Vector__XXX
 SG_ BMS_Section_3_Temp : 16|16@1+ (0.1,0) [0|6] "C" Vector__XXX
 SG_ BMS_Section_4_Temp : 0|16@1+ (0.1,0) [0|6] "C" Vector__XXX

BO_ 1919 UNUSED: 8 DAQ
 SG_ S2C_MPRLS0_Pressure : 0|32@1+ (0.01,0) [0|100000] "hPa" S2C
 SG_ S2C_MPRLS1_Pressure : 32|32@1+ (0.01,0) [0|100000] "hPa" S2C

CM_ BU_ VCU "The vehicle control unit";
CM_ BU_ MCM "The motor controller of the car";
CM_ BU_ BMS "The battery management system";
CM_ BU_ DCU "The dash control unit";
CM_ BO_ 160 "Motor Controller Temperatures Set 1";
CM_ BO_ 161 "Motor Controller Temperatures Set 2";
CM_ BO_ 162 "Motor Controller Temperatures Set 3";
CM_ BO_ 165 "Motor Position Information";
CM_ BO_ 166 "Motor Current Information";
CM_ BO_ 167 "Motor Voltage Information";
CM_ BO_ 192 "Motor Controller Command Messages";
CM_ BO_ 1280 "Throttle Position Sensor 0 Value";
CM_ BO_ 1281 "Throttle Position Sensor 1 Value";
CM_ BO_ 1282 "Brake Pressure Sensor Value";
CM_ BO_ 1283 "VCU software-differential debug frame (multipliers scaled 0.001)";
CM_ BO_ 1284 "VCU steering-angle sensor";
CM_ BO_ 1285 "VCU Safety Messages";
CM_ BO_ 1286 "24 V low-voltage battery and SOC";
CM_ BO_ 1287 "HVIL termination sense";
CM_ BO_ 1288 "VCU BMS debug";
CM_ BO_ 1568 "BMS Status and Fault Message";
CM_ BO_ 1571 "Accumulator Pack Voltage and Current";
CM_ BO_ 1572 "Accumulator Load Voltage and Current";
CM_ BO_ 1573 "Cell Voltage High and Low";
CM_ BO_ 1574 "Cell Voltage Average and Mismatch";
CM_ BO_ 1575 "SOC Percentage and Battery Capacity";
CM_ BO_ 1576 "Cell and BMS Board Temperature Average";
CM_ BO_ 1577 "Cell Temperature High and Low";
CM_ BO_ 1584 "BMS Board Temperature High and Low";
CM_ BO_ 1585 "Accumulator Load Power";
CM_ BO_ 1793 "Dash Control Unit Timestamp";
CM_ BO_ 2023 "This CAN id is used for communication between the energy meter and the download tool.";
CM_ BO_ 2031 "This CAN id is used for communication between the energy meter and the download tool.";
CM_ BU_ BMS1000M "BMS Master Controller";
CM_ BU_ VCU "Vehicle Control Unit or Master System Controller";
CM_ BO_ 1536 "Sent when BMS state transition is needed";
CM_ BO_ 1538 "Sent every 100ms";
CM_ BO_ 1552 "Sent every 100ms";
CM_ BO_ 1553 "Sent every 100ms";
CM_ BO_ 1554 "Sent every 100ms";
CM_ BO_ 1568 "Sent every 100ms";
CM_ SG_ 1568 BMS_Pack_Current "Charging is positive";
CM_ BO_ 1569 "Sent every 100ms";
CM_ BO_ 1570 "Sent every 100ms";
CM_ BO_ 1571 "Sent every 100ms";
CM_ BO_ 1788 "Sent every 1 second";
CM_ BO_ 1788 "Sent every 1 second";
CM_ BO_ 1572 "Sent every 100ms";

BA_DEF_ "BusType" STRING ;
BA_DEF_ SG_ "FieldType" STRING ;

BA_DEF_DEF_ "BusType" "CAN";
BA_DEF_DEF_ "FieldType" "";

BA_ "FieldType" SG_ 100 DRIVER_HEARTBEAT_cmd "DRIVER_HEARTBEAT_cmd";

VAL_ 100 DRIVER_HEARTBEAT_cmd 2 "DRIVER_HEARTBEAT_cmd_REBOOT" 1 "DRIVER_HEARTBEAT_cmd_SYNC" 0 "DRIVER_HEARTBEAT_cmd_NOOP" ;
VAL_ 1024 CurrentGain 0 "x1" 1 "x2" 2 "x4" 3 "x8" 4 "x16" 5 "x32" ;
VAL_ 1024 Logging 0 "x1" 1 "x2" 2 "x4" 3 "x8" 4 "x16" 5 "x32" ;
VAL_ 1536 BMS_State_Request 0 "No State Change Requested" 1 "Request BMS Sleep" 2 "Request BMS Idle" 3 "Request BMS Pre-charge" 4 "Request Clear Faults" ;
VAL_ 1538 BMS_Imminent_Contactor_Opening_Warning 0 "Contactors will not open within 2 seconds" 1 "Contactors will open within 2 seconds due to fault condition" ;
VAL_ 1552 BMS_Current_State 0 "BMS Internal Error" 1 "BMS Sleep" 2 "BMS Startup" 3 "BMS Idle" 4 "BMS Pre-charge" 5 "BMS Active" 6 "BMS Fault" ;

CM_ BO_ 2147483904 "VESC CAN_PACKET_SET_CURRENT (packet id 1) to controller 0 = RR. 29-bit extended frame, payload is int32 motor current in mA, MSB first.";
CM_ BO_ 2147483905 "VESC CAN_PACKET_SET_CURRENT (packet id 1) to controller 1 = RL. 29-bit extended frame, payload is int32 motor current in mA, MSB first.";
